VERSION ""

NS_ :

BS_:

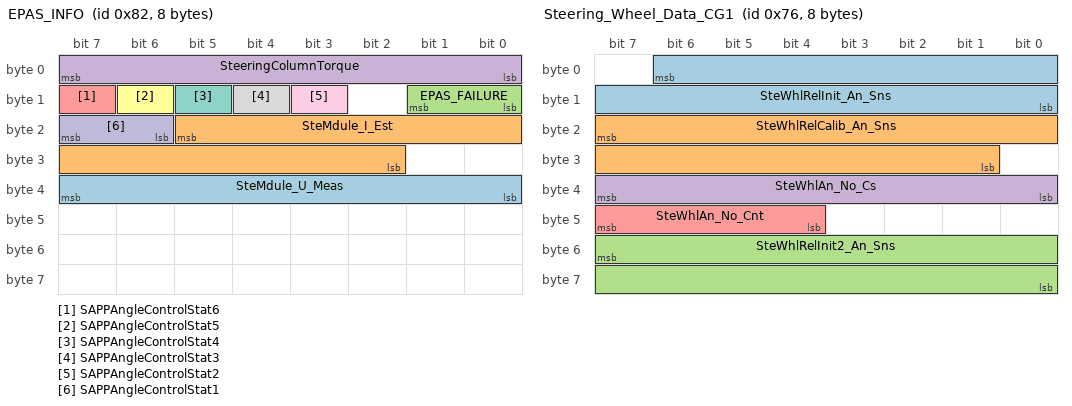
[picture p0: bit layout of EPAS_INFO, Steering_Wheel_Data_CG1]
BO_ 130 EPAS_INFO: 8 XXX
 SG_ SteMdule_U_Meas : 39|8@0+ (0.05,6.0) [0|0] "Volts" XXX
 SG_ SteMdule_I_Est : 21|12@0+ (0.05,-64.0) [0|0] "Amps" XXX
 SG_ EPAS_FAILURE : 9|2@0+ (1,0) [0|0] "" XXX
 SG_ SteeringColumnTorque : 7|8@0+ (0.0625,-8.0) [0|0] "Nm" XXX
 SG_ SAPPAngleControlStat6 : 15|1@0+ (1,0) [0|0] "" XXX
 SG_ SAPPAngleControlStat5 : 14|1@0+ (1,0) [0|0] "" XXX
 SG_ SAPPAngleControlStat4 : 13|1@0+ (1,0) [0|0] "" XXX
 SG_ SAPPAngleControlStat3 : 12|1@0+ (1,0) [0|0] "" XXX
 SG_ SAPPAngleControlStat2 : 11|1@0+ (1,0) [0|0] "" XXX
 SG_ SAPPAngleControlStat1 : 23|2@0+ (1,0) [0|0] "" XXX

BO_ 118 Steering_Wheel_Data_CG1: 8 XXX
 SG_ SteWhlRelInit_An_Sns : 6|15@0+ (0.1,-1600.0) [0|0] "deg" XXX
 SG_ SteWhlRelCalib_An_Sns : 23|15@0+ (0.1,-1600.0) [0|0] "deg" XXX
 SG_ SteWhlRelInit2_An_Sns : 55|16@0+ (0.1,-3200.0) [0|0] "deg" XXX
 SG_ SteWhlAn_No_Cs : 39|8@0+ (1,0) [0|0] "" XXX
 SG_ SteWhlAn_No_Cnt : 47|4@0+ (1,0) [0|0] "Counts" XXX

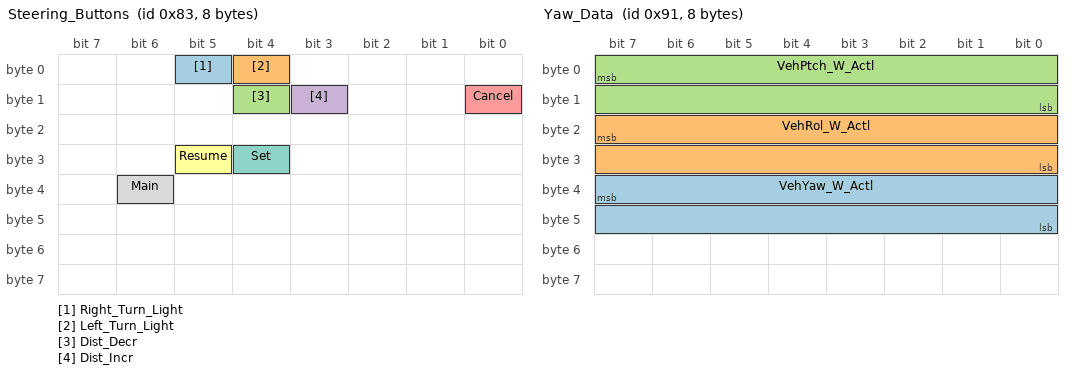
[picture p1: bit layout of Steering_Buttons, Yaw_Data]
BO_ 131 Steering_Buttons: 8 XXX
 SG_ Right_Turn_Light : 5|1@0+ (1,0) [0|0] "" XXX
 SG_ Left_Turn_Light : 4|1@0+ (1,0) [0|0] "" XXX
 SG_ Dist_Decr : 12|1@0+ (1,0) [0|0] "" XXX
 SG_ Dist_Incr : 11|1@0+ (1,0) [0|0] "" XXX
 SG_ Cancel : 8|1@0+ (1,0) [0|0] "" XXX
 SG_ Resume : 29|1@0+ (1,0) [0|0] "" XXX
 SG_ Set : 28|1@0+ (1,0) [0|0] "" XXX
 SG_ Main : 38|1@0+ (1,0) [0|0] "" XXX

BO_ 145 Yaw_Data: 8 XXX
 SG_ VehYaw_W_Actl : 39|16@0+ (0.0002,-6.5) [0|0] "rad/s" XXX
 SG_ VehRol_W_Actl : 23|16@0+ (0.0002,-6.5) [0|0] "rad/s" XXX
 SG_ VehPtch_W_Actl : 7|16@0+ (0.0002,-6.5) [0|0] "rad/s" XXX

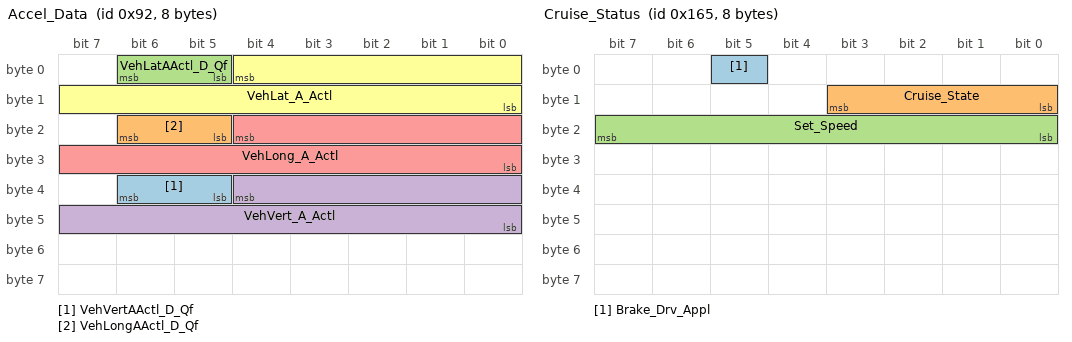
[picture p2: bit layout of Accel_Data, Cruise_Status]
BO_ 146 Accel_Data: 8 XXX
 SG_ VehVertAActl_D_Qf : 38|2@0+ (1,0) [0|0] "" XXX
 SG_ VehLongAActl_D_Qf : 22|2@0+ (1,0) [0|0] "" XXX
 SG_ VehLatAActl_D_Qf : 6|2@0+ (1,0) [0|0] "" XXX
 SG_ VehVert_A_Actl : 36|13@0+ (0.01,-40.0) [0|0] "m/s^2" XXX
 SG_ VehLong_A_Actl : 20|13@0+ (0.01,-40.0) [0|0] "m/s^2" XXX
 SG_ VehLat_A_Actl : 4|13@0+ (0.01,-40.0) [0|0] "m/s^2" XXX

BO_ 357 Cruise_Status: 8 XXX
 SG_ Brake_Drv_Appl : 5|1@0+ (1,0) [0|0] "" XXX
 SG_ Cruise_State : 11|4@0+ (1,0) [0|0] "" XXX
 SG_ Set_Speed : 23|8@0+ (1,0) [0|0] "" XXX

BO_ 516 EngineData_14: 8 XXX
 SG_ ApedPosScal_Pc_Actl : 1|10@0+ (0.1,0) [0|0] "%" XXX

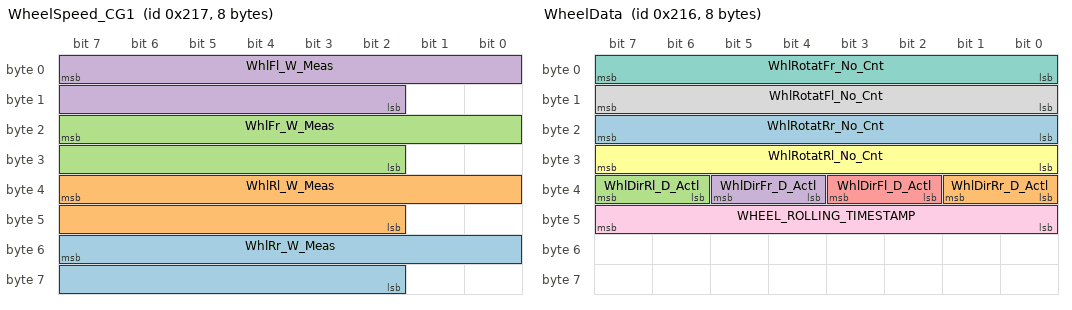
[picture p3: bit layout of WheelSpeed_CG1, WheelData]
BO_ 535 WheelSpeed_CG1: 8 XXX
 SG_ WhlRr_W_Meas : 55|14@0+ (0.04,0) [0|0] "rad/s" XXX
 SG_ WhlRl_W_Meas : 39|14@0+ (0.04,0) [0|0] "rad/s" XXX
 SG_ WhlFr_W_Meas : 23|14@0+ (0.04,0) [0|0] "rad/s" XXX
 SG_ WhlFl_W_Meas : 7|14@0+ (0.04,0) [0|0] "rad/s" XXX

BO_ 534 WheelData: 8 XXX
 SG_ WhlRotatRr_No_Cnt : 23|8@0+ (1,0) [0|0] "" XXX
 SG_ WhlDirRr_D_Actl : 33|2@0+ (1,0) [0|0] "" XXX
 SG_ WhlDirRl_D_Actl : 39|2@0+ (1,0) [0|0] "" XXX
 SG_ WhlDirFr_D_Actl : 37|2@0+ (1,0) [0|0] "" XXX
 SG_ WhlDirFl_D_Actl : 35|2@0+ (1,0) [0|0] "" XXX
 SG_ WhlRotatRl_No_Cnt : 31|8@0+ (1,0) [0|0] "" XXX
 SG_ WhlRotatFr_No_Cnt : 7|8@0+ (1,0) [0|0] "" XXX
 SG_ WhlRotatFl_No_Cnt : 15|8@0+ (1,0) [0|0] "" XXX
 SG_ WHEEL_ROLLING_TIMESTAMP : 47|8@0+ (1,0) [0|0] "" XXX

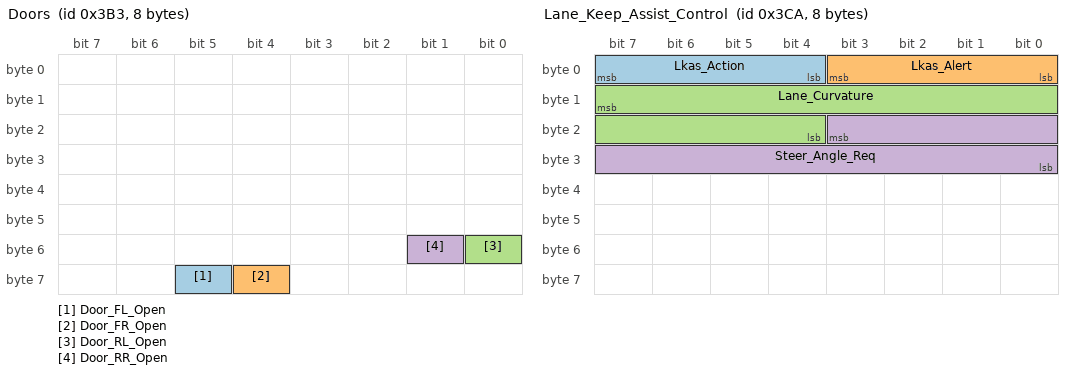
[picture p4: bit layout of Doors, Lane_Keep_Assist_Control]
BO_ 947 Doors: 8 XXX
 SG_ Door_FL_Open : 61|1@0+ (1,0) [0|0] "" XXX
 SG_ Door_FR_Open : 60|1@0+ (1,0) [0|0] "" XXX
 SG_ Door_RL_Open : 48|1@0+ (1,0) [0|0] "" XXX
 SG_ Door_RR_Open : 49|1@0+ (1,0) [0|0] "" XXX

BO_ 963 BCM_to_HS_Body: 8 XXX
 SG_ Brake_Lights : 8|1@0+ (1,0) [0|0] "" XXX

BO_ 970 Lane_Keep_Assist_Control: 8 XXX
 SG_ Lkas_Action : 7|4@0+ (1,0) [0|15] "" XXX
 SG_ Lkas_Alert : 3|4@0+ (1,0) [0|15] "" XXX
 SG_ Lane_Curvature : 15|12@0+ (5e-06,-0.01) [0|0] "1/m" XXX
 SG_ Steer_Angle_Req : 19|12@0+ (0.04297,-88.00445) [0|0] "deg" XXX

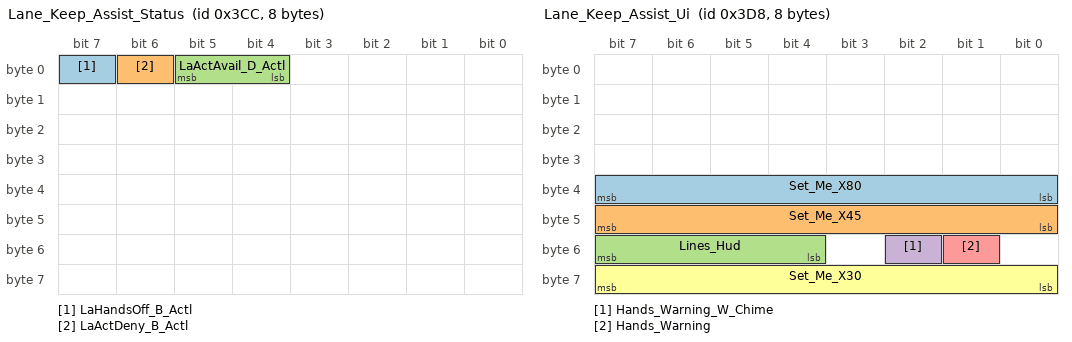
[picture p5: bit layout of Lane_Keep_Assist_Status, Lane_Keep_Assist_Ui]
BO_ 972 Lane_Keep_Assist_Status: 8 XXX
 SG_ LaHandsOff_B_Actl : 7|1@0+ (1,0) [0|0] "" XXX
 SG_ LaActDeny_B_Actl : 6|1@0+ (1,0) [0|0] "" XXX
 SG_ LaActAvail_D_Actl : 5|2@0+ (1,0) [0|0] "" XXX

BO_ 984 Lane_Keep_Assist_Ui: 8 XXX
 SG_ Set_Me_X80 : 39|8@0+ (1,0) [0|255] "" XXX
 SG_ Set_Me_X45 : 47|8@0+ (1,0) [0|255] "" XXX
 SG_ Lines_Hud : 55|4@0+ (1,0) [0|15] "" XXX
 SG_ Hands_Warning_W_Chime : 50|1@0+ (1,0) [0|1] "" XXX
 SG_ Hands_Warning : 49|1@0+ (1,0) [0|1] "" XXX
 SG_ Set_Me_X30 : 63|8@0+ (1,0) [0|255] "" XXX

BU_: XXX

CM_ BU_ K16_BECM "Battery Energy Control Module";
CM_ BU_ K73_TCIC "Telematics Communication Control Module";
CM_ BU_ K9_BCM "Body Control Module";
CM_ BU_ K43_PSCM "Power Steering Control Module";
CM_ BU_ K17_EBCM "Electronic Brake Control Module";
CM_ BU_ K20_ECM "Engine Control Module";
CM_ BU_ K114B_HPCM "Hybrid Powertrain Control Module";
CM_ BU_ NEO "Comma NEO";
CM_ BU_ K124_ASCM "Active Safety Control Module";
CM_ SG_ 381 MSG17D_AccPower "Need to investigate";
CM_ SG_ 190 GasPedalAndAcc "ACC baseline is 62";
CM_ SG_ 451 GasPedalAndAcc2 "ACC baseline is 62";
CM_ SG_ 715 RollingCounter2 "Values cycle between 0, 7, 10, 13";
BA_DEF_  "UseGMParameterIDs" INT 0 0;
BA_DEF_  "ProtocolType" STRING ;
BA_DEF_  "BusType" STRING ;
BA_DEF_DEF_  "UseGMParameterIDs" 1;
BA_DEF_DEF_  "ProtocolType" "GMLAN";
BA_DEF_DEF_  "BusType" "";
BA_ "BusType" "CAN";
BA_ "UseGMParameterIDs" 0;
